# K1921VG1T register map
Vendor: NIIET; Series: K1921VGx; File version: 2.8
CPU: other r0p1, little endian, MPU, FPU, 4 interrupt priority bits
Registers are 32-bit, read-write, reset 0x0 unless marked. A register's access mark holds for its fields unless they carry their own. Offsets are from the block's base; [hi:lo] are bit positions; lines under a group give offsets from that group; {n}, {i} and the like mark numbered series; <NAME> marks a mode.

## CRC — Cyclic redundancy check module
Base 0x41050000
0x00 DR reset 0xFFFFFFFF — CRC Data register
  [31:0] VAL — Data register
0x04 POST ro — CRC post register
  [31:0] VAL — Post-processing CRC value
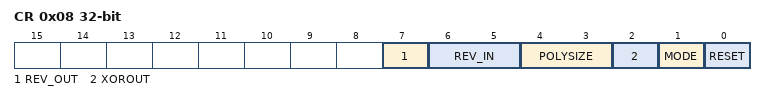
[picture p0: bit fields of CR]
0x08 CR — CRC control register
  [7] REV_OUT — Reverse output data
    0=Disable (Bit order not affected); 1=Enable (Bit-reversed output format)
  [6:5] REV_IN — Reverse input data. These bits control the reversal of the bit order of the input data
    0=Disable (Bit order not affected(default)); 1=REV_BYTE (Bit reversal done by byte); 2=REV_HALFWORD (Bit reversal done by half-word); 3=REV_WORD (Bit reversal done by word)
  [4:3] POLYSIZE ro — Polynomial size. These bits control the size of the polynomial
    0=POL32 (32 bit polynomial); 1=POL16 (16 bit polynomial); 2=POL8 (8 bit polynomial); 3=POL7 (7 bit polynomial)
  [2] XOROUT — XOR for data out
    0=Disable (Output XOR operation is disabled); 1=Enable (Output XOR operation is enabled)
  [1] MODE — Mode calc CRC
    0=StandartCRC (Standart mode); 1=STM32_CRC (STM32 compatible mode)
  [0] RESET wo — RESET bit
0x0C INIT reset 0xFFFFFFFF — CRC initial value register
  [31:0] VAL — Initial CRC value
0x10 POL reset 0x4C11DB7 — CRC polynomial register
  [31:0] VAL — Programmable polynomial value

## HASH — HASH registers
Base 0x41060000
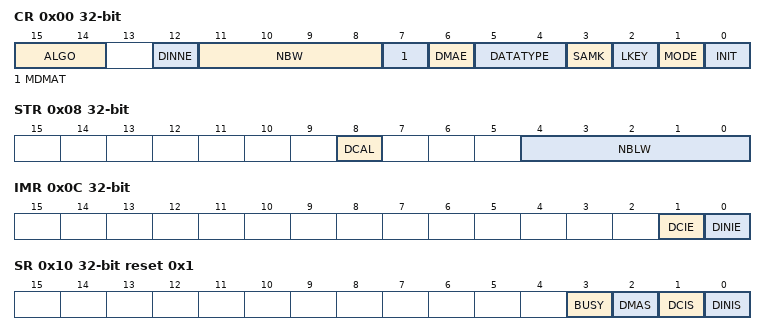
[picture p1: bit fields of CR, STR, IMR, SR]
0x00 CR — Control register
  [15:14] ALGO — Algorithm selection
    0=SHA1 (SHA-1 algorithm selected); 1=MD5 (MD5 algorithm selected); 2=SHA224 (SHA224 algorithm selected); 3=SHA256 (SHA256 algorithm selected)
  [12] DINNE ro — DIN not empty
  [11:8] NBW ro — Number of words already pushed
  [7] MDMAT — Multiple DMA transfers
  [6] DMAE — DMA enable
  [5:4] DATATYPE — Datatype selection
    0=WORD (32-bit data. The data written into HASH_DIN are directly used by the HASH processing, without reordering); 1=HWORD (16-bit data, or half-word. The data written into HASH_DIN are considered as 2 half-words, and are swapped before being used by the HASH processing); 2=BYTE (8-bit data, or bytes. The data written into HASH_DIN are considered as 4 bytes, and are swapped before being used by the HASH processing); 3=BIT (bit data, or bit-string. The data written into HASH_DIN are considered as 32bits (1st bit of the sting at position 0), and are swapped before being used by the HASH processing (1st bit of the string at position 31))
  [3] SAMK — Same key option
  [2] LKEY — Long key selection
    0=HMAC_SHORT_KEY (Short key (≤ 64 bytes)); 1=HMAC_LONG_KEY (Long key (> 64 bytes))
  [1] MODE — Mode selection
    0=HASH (Hash mode selected); 1=HMAC (HMAC mode selected. LKEY must be set if the key being used is longer than 64 bytes. SAMK option for long key must be set if the keys used for inner/outer hash functions are identical)
  [0] INIT wo — Initialize message digest calculation
0x04 DATAIN — Data input register
  [31:0] VAL — Data input
0x08 STR — Start register
  [8] DCAL wo — Digest calculation
  [4:0] NBLW — Number of valid bits in the last word of the message
0x0C IMR — Interrupt enable register
  [1] DCIE — Digest calculation completion interrupt enable
  [0] DINIE — Data input interrupt enable
0x10 SR reset 0x1 — Interrupt status register
  [3] BUSY ro — Busy bit
  [2] DMAS ro — DMA status
  [1] DCIS wo — Digest calculation completion interrupt status
  [0] DINIS wo — Data input interrupt status
{0x40+4i} HR[{i}] (i=0..7) group
  0x00 VALUE ro — Hash digest register
    [31:0] VAL

## CRYPTO — Cryptographic calculation support module
Base 0x41070000
{0x0+4i} IV[{i}] (i=0..3) group
  0x00 VALUE — Initialization vector register 0
    [31:0] VAL — Initialization vector register (word i). Bits 32*(4-i)-1 to 32*(3-i) for AES_128, AES_256, Kuznechik / Bits 32*(2-i)-1 to 32*(1-i) for Magma (i < 2)
{0x10+4i} TEXT_IN[{i}] (i=0..3) group
  0x00 VALUE — Input text regiter 0 (plain text / cipher text)
    [31:0] VAL — Text in registers (word i). Bits 32*(4-i)-1 to 32*(3-i) for AES_128, AES_256, Kuznechik / Bits 32*(2-i)-1 to 32*(1-i) for Magma (i < 2)
{0x20+4i} KEY[{i}] (i=0..7) group
  0x00 VALUE — Secret key register 0
    [31:0] VAL — Key registers (word i). Bits 32*(8-i)-1 to 32*(7-i) for AES_256, Magma, Kuznechik / Bits 32*(4-i)-1 to 32*(3-i) for AES_128 (i < 4)
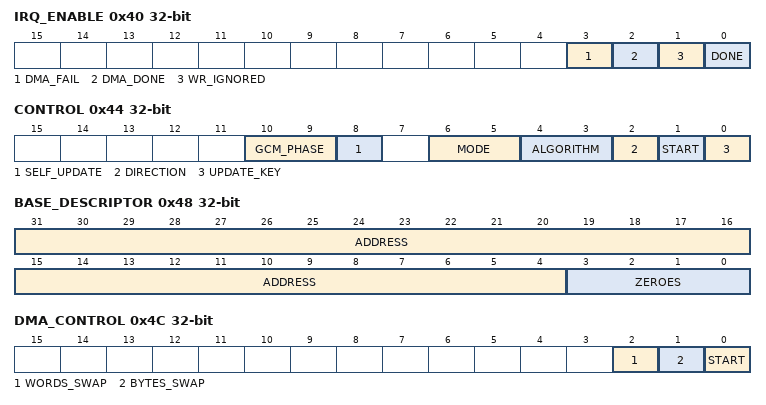
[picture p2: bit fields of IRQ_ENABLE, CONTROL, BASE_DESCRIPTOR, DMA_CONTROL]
0x40 IRQ_ENABLE — Interrupt enable register
  [3] DMA_FAIL, [2] DMA_DONE ro, [1] WR_IGNORED, [0] DONE
0x44 CONTROL — Operation control register
  [10:9] GCM_PHASE
    0=GCM_INIT (GCM initialization phase); 1=GCM_HEADER (GCM header phase); 2=GCM_PAYLOAD (GCM payload phase); 3=GCM_LAST_BLOCK (GCM last block phase)
  [8] SELF_UPDATE
  [6:5] MODE
    0=ECB (Electronic Codebook mode (ECB)); 1=CBC (Cipher Block Chaining mode (CBC)); 2=CTR (Counter mode (CTR)); 3=GCM (Galois/Counter mode (GCM))
  [4:3] ALGORITHM
    0=AES_128 (AES 128 bit key); 1=AES_256 (AES 256 bit key); 2=Magma (GOST 34.12-2018 cipher with 64 bit block (Magma)); 3=Kuznechik (GOST 34.12-2018 cipher with 128 bit block (Kuznechik))
  [2] DIRECTION
    0=Encrypt (Do encryption); 1=Decrypt (Do decryption)
  [1] START wo
  [0] UPDATE_KEY wo
0x48 BASE_DESCRIPTOR — Register of address of base descriptor
  [31:4] ADDRESS, [3:0] ZEROES ro
0x4C DMA_CONTROL — DMA operations control register
  [2] WORDS_SWAP, [1] BYTES_SWAP, [0] START wo
0x50 TERMINATE wo — Operation emergency terminate register (write of 0xD0 terminate current oeparation)
  [7:0] CODE
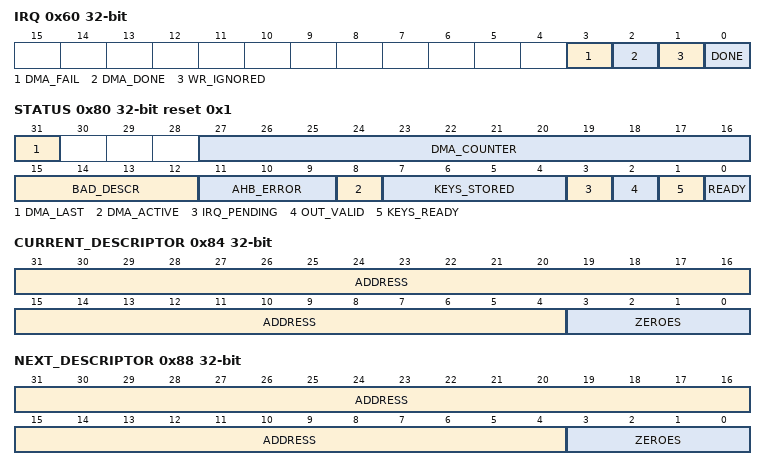
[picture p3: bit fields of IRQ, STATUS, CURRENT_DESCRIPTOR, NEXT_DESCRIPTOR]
0x60 IRQ — Interrupts pending register
  [3] DMA_FAIL, [2] DMA_DONE, [1] WR_IGNORED, [0] DONE
{0x70+4i} TEXT_OUT[{i}] (i=0..3) group
  0x00 VALUE ro — Output text regiter 0 (cipher text / plain text)
    [31:0] VAL — Text out registers (word i). Bits 32*(4-i)-1 to 32*(3-i) for AES_128, AES_256, Kuznechik / Bits 32*(2-i)-1 to 32*(1-i) for Magma (i < 2)
0x80 STATUS ro reset 0x1 — Operation status register
  [31] DMA_LAST, [27:16] DMA_COUNTER, [15:12] BAD_DESCR, [11:9] AHB_ERROR, [8] DMA_ACTIVE, [7:4] KEYS_STORED, [3] IRQ_PENDING, [2] OUT_VALID, [1] KEYS_READY, [0] READY
0x84 CURRENT_DESCRIPTOR ro — Register of address of current handling descriptor
  [31:4] ADDRESS, [3:0] ZEROES
0x88 NEXT_DESCRIPTOR ro — Register of address of next descriptor
  [31:4] ADDRESS, [3:0] ZEROES
